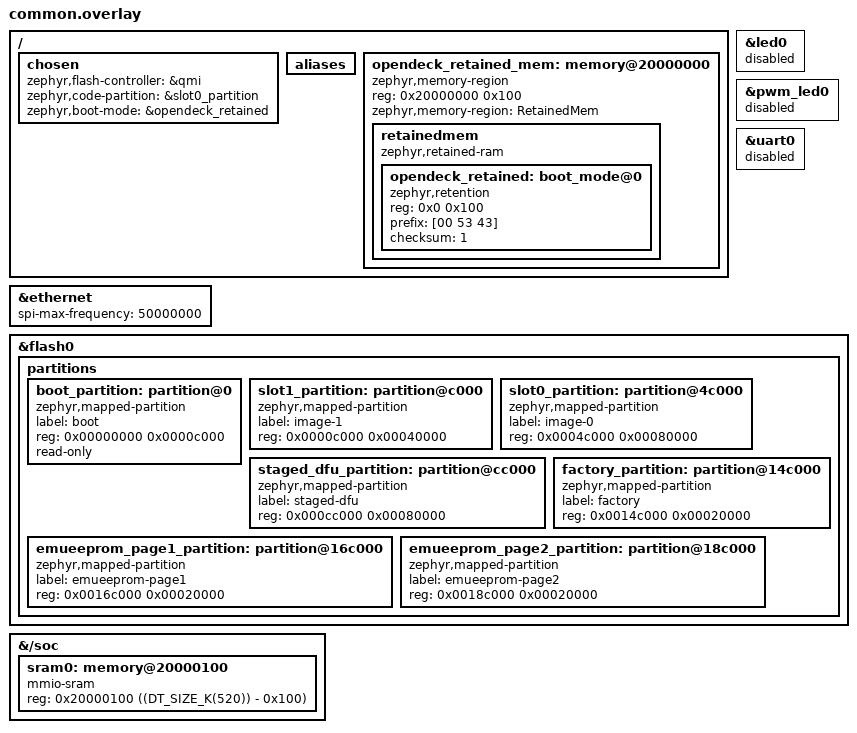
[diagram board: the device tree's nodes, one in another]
/ {
    chosen {
        zephyr,flash-controller = &qmi;
        /delete-property/ zephyr,console;
        /delete-property/ zephyr,shell-uart;
    };

    aliases {
        /delete-property/ led0;
        /delete-property/ pwm-led0;
    };
};

&led0 {
    status = "disabled";
};

&pwm_led0 {
    status = "disabled";
};

&uart0 {
    status = "disabled";
};

&ethernet {
    /delete-property/ local-mac-address;
    spi-max-frequency = <50000000>;
};

&flash0 {
    #address-cells = <1>;
    #size-cells = <1>;
    ranges = <0x0 0x10000000 DT_SIZE_M(2)>;

    /delete-node/ partitions;

    partitions {
        ranges;
        #address-cells = <1>;
        #size-cells = <1>;

        boot_partition: partition@0 {
            compatible = "zephyr,mapped-partition";
            label = "boot";
            reg = <0x00000000 0x0000c000>;
            read-only;
        };

        /* image-1 is the OpenDeck bootloader; keep it before image-0 so merged UF2 files stay compact. */
        slot1_partition: partition@c000 {
            compatible = "zephyr,mapped-partition";
            label = "image-1";
            reg = <0x0000c000 0x00040000>;
        };

        slot0_partition: partition@4c000 {
            compatible = "zephyr,mapped-partition";
            label = "image-0";
            reg = <0x0004c000 0x00080000>;
        };

        staged_dfu_partition: partition@cc000 {
            compatible = "zephyr,mapped-partition";
            label = "staged-dfu";
            reg = <0x000cc000 0x00080000>;
        };

        factory_partition: partition@14c000 {
            compatible = "zephyr,mapped-partition";
            label = "factory";
            reg = <0x0014c000 0x00020000>;
        };

        emueeprom_page1_partition: partition@16c000 {
            compatible = "zephyr,mapped-partition";
            label = "emueeprom-page1";
            reg = <0x0016c000 0x00020000>;
        };

        emueeprom_page2_partition: partition@18c000 {
            compatible = "zephyr,mapped-partition";
            label = "emueeprom-page2";
            reg = <0x0018c000 0x00020000>;
        };
    };
};

/delete-node/ &sram0;

&{/soc} {
    sram0: memory@20000100 {
        compatible = "mmio-sram";
        reg = <0x20000100 ((DT_SIZE_K(520)) - 0x100)>;
    };
};

/ {
    chosen {
        zephyr,code-partition = &slot0_partition;
        zephyr,boot-mode = &opendeck_retained;
    };

    opendeck_retained_mem: memory@20000000 {
        compatible = "zephyr,memory-region", "mmio-sram";
        reg = <0x20000000 0x100>;
        zephyr,memory-region = "RetainedMem";
        status = "okay";

        retainedmem {
            compatible = "zephyr,retained-ram";
            status = "okay";
            #address-cells = <1>;
            #size-cells = <1>;

            opendeck_retained: boot_mode@0 {
                compatible = "zephyr,retention";
                status = "okay";
                reg = <0x0 0x100>;
                prefix = [00 53 43];
                checksum = <1>;
            };
        };
    };
};
